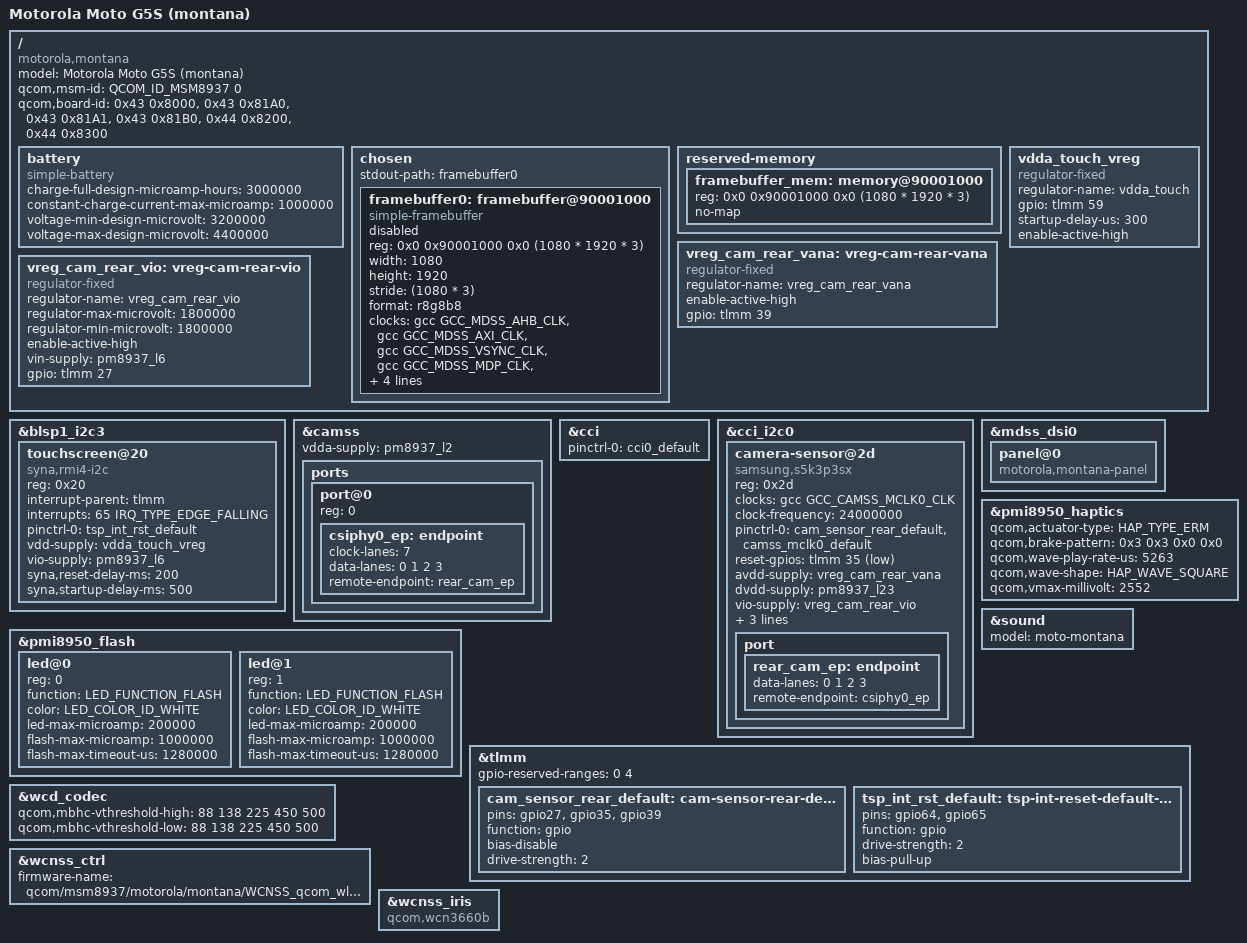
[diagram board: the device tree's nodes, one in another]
// SPDX-License-Identifier: BSD-3-Clause
/*
 * Copyright (c) 2024, Barnabas Czeman
 */

/dts-v1/;

#include "msm8937.dtsi"
#include "msm8937-msm8917-motorola-common.dtsi"

/ {
	model = "Motorola Moto G5S (montana)";
	compatible = "motorola,montana", "qcom,msm8937";
	qcom,msm-id = <QCOM_ID_MSM8937 0>;
	qcom,board-id = <0x43 0x8000>,
			<0x43 0x81A0>,
			<0x43 0x81A1>,
			<0x43 0x81B0>,
			<0x44 0x8200>,
			<0x44 0x8300>;

	battery: battery {
		compatible = "simple-battery";

		charge-full-design-microamp-hours = <3000000>;
		constant-charge-current-max-microamp = <1000000>;
		voltage-min-design-microvolt = <3200000>;
		voltage-max-design-microvolt = <4400000>;
	};

	chosen {
		#address-cells = <2>;
		#size-cells = <2>;
		ranges;

		stdout-path = "framebuffer0";

		framebuffer0: framebuffer@90001000 {
			compatible = "simple-framebuffer";
			reg = <0x0 0x90001000 0x0 (1080 * 1920 * 3)>;
			width = <1080>;
			height = <1920>;
			stride = <(1080 * 3)>;
			format = "r8g8b8";

			clocks = <&gcc GCC_MDSS_AHB_CLK>,
				 <&gcc GCC_MDSS_AXI_CLK>,
				 <&gcc GCC_MDSS_VSYNC_CLK>,
				 <&gcc GCC_MDSS_MDP_CLK>,
				 <&gcc GCC_MDSS_BYTE0_CLK>,
				 <&gcc GCC_MDSS_PCLK0_CLK>,
				 <&gcc GCC_MDSS_ESC0_CLK>;
			power-domains = <&gcc MDSS_GDSC>;
			status = "disabled";
		};
	};

	reserved-memory {
		framebuffer_mem: memory@90001000 {
			reg = <0x0 0x90001000 0x0 (1080 * 1920 * 3)>;
			no-map;
		};
	};

	vdda_touch_vreg: vdda_touch_vreg {
		compatible = "regulator-fixed";
		regulator-name = "vdda_touch";
		gpio = <&tlmm 59 GPIO_ACTIVE_HIGH>;
		startup-delay-us = <300>;
		enable-active-high;
	};

	vreg_cam_rear_vana: vreg-cam-rear-vana {
		compatible = "regulator-fixed";
		regulator-name = "vreg_cam_rear_vana";
		enable-active-high;
		gpio = <&tlmm 39 GPIO_ACTIVE_HIGH>;
	};

	vreg_cam_rear_vio: vreg-cam-rear-vio {
		compatible = "regulator-fixed";
		regulator-name = "vreg_cam_rear_vio";
		regulator-max-microvolt = <1800000>;
		regulator-min-microvolt = <1800000>;
		enable-active-high;
		vin-supply = <&pm8937_l6>;
		gpio = <&tlmm 27 GPIO_ACTIVE_HIGH>;
	};
};

&blsp1_i2c3 {
	status = "okay";

	touchscreen@20 {
		compatible = "syna,rmi4-i2c";
		reg = <0x20>;

		interrupt-parent = <&tlmm>;
		interrupts = <65 IRQ_TYPE_EDGE_FALLING>;

		pinctrl-0 = <&tsp_int_rst_default>;
		pinctrl-names = "default";

		vdd-supply = <&vdda_touch_vreg>;
		vio-supply = <&pm8937_l6>;

		syna,reset-delay-ms = <200>;
		syna,startup-delay-ms = <500>;
	};
};

&camss {
	vdda-supply = <&pm8937_l2>;
	status = "okay";

	ports {
		port@0 {
			reg = <0>;

			csiphy0_ep: endpoint {
				clock-lanes = <7>;
				data-lanes = <0 1 2 3>;
				remote-endpoint = <&rear_cam_ep>;
			};
		};
	};
};

&cci {
	pinctrl-0 = <&cci0_default>;
	pinctrl-names = "default";

	status = "okay";
};

&cci_i2c0 {
	camera-sensor@2d {
		compatible = "samsung,s5k3p3sx";

		reg = <0x2d>;

		clocks = <&gcc GCC_CAMSS_MCLK0_CLK>;
		clock-frequency = <24000000>;

		pinctrl-0 = <&cam_sensor_rear_default>, <&camss_mclk0_default>;
		pinctrl-names = "default";

		reset-gpios = <&tlmm 35 GPIO_ACTIVE_LOW>;

		avdd-supply= <&vreg_cam_rear_vana>;
		dvdd-supply = <&pm8937_l23>;
		vio-supply = <&vreg_cam_rear_vio>;
		aux-supply = <&pm8937_l17>;

		orientation = <1>;
		rotation = <270>;

		port {
			rear_cam_ep: endpoint {
				data-lanes = <0 1 2 3>;
				remote-endpoint = <&csiphy0_ep>;
			};
		};
	};
};

&mdss_dsi0 {
	panel@0 {
		compatible = "motorola,montana-panel";
	};
};

&pmi8950_flash {
	#address-cells = <1>;
	#size-cells = <0>;
	status = "okay";

	led@0 {
		reg = <0>;
		function = LED_FUNCTION_FLASH;
		color = <LED_COLOR_ID_WHITE>;
		led-max-microamp = <200000>;
		flash-max-microamp = <1000000>;
		flash-max-timeout-us = <1280000>;
	};

	led@1 {
		reg = <1>;
		function = LED_FUNCTION_FLASH;
		color = <LED_COLOR_ID_WHITE>;
		led-max-microamp = <200000>;
		flash-max-microamp = <1000000>;
		flash-max-timeout-us = <1280000>;
	};
};

&pmi8950_haptics {
	qcom,actuator-type = <HAP_TYPE_ERM>;
	qcom,brake-pattern = <0x3 0x3 0x0 0x0>;
	qcom,wave-play-rate-us = <5263>;
	qcom,wave-shape = <HAP_WAVE_SQUARE>;
	qcom,vmax-millivolt = <2552>;

	status = "okay";
};

&sound {
	model = "moto-montana";
};

&tlmm {
	gpio-reserved-ranges = <0 4>;

	cam_sensor_rear_default: cam-sensor-rear-default-state {
		pins = "gpio27", "gpio35", "gpio39";
		function = "gpio";
		bias-disable;
		drive-strength = <2>;
	};

	tsp_int_rst_default: tsp-int-reset-default-state {
		pins = "gpio64", "gpio65";
		function = "gpio";
		drive-strength = <2>;
		bias-pull-up;
	};
};

&wcd_codec {
	qcom,mbhc-vthreshold-high = <88 138 225 450 500>;
	qcom,mbhc-vthreshold-low = <88 138 225 450 500>;
};

&wcnss_ctrl {
	firmware-name = "qcom/msm8937/motorola/montana/WCNSS_qcom_wlan_nv.bin";
};

&wcnss_iris {
	compatible = "qcom,wcn3660b";
};
